# STM32U5Gx register map
File version: 1.0
CPU: CM33 r0p1, little endian, MPU, FPU, 4 interrupt priority bits
Registers are 32-bit, read-write, reset 0x0 unless marked. A register's access mark holds for its fields unless they carry their own. Offsets are from the block's base; [hi:lo] are bit positions.

## ADC12_Common — Analog-to-Digital Converter
Base 0x42028300
Same registers: SEC_ADC12_Common 0x52028300
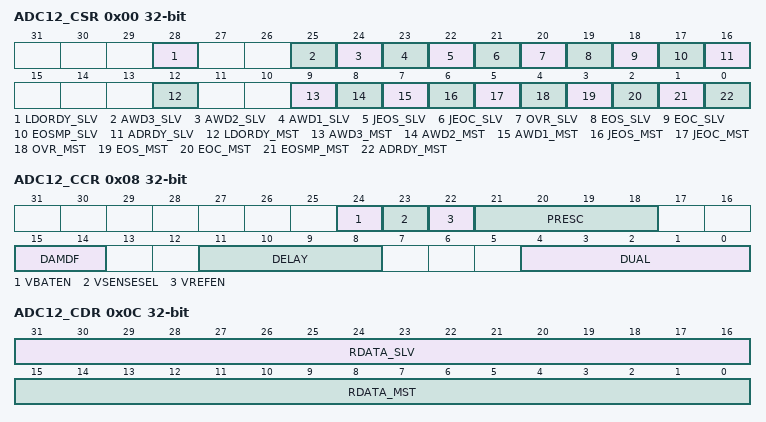
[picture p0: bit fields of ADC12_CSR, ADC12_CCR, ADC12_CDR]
0x00 ADC12_CSR ro — ADC common status register
  [28] LDORDY_SLV — ADC voltage regulator ready flag of the slave ADC This bit is a copy of the LDORDY bit of the corresponding ADCx+1_ISR register.
  [25] AWD3_SLV — Analog watchdog 3 flag of the slave ADC This bit is a copy of the AWD3 bit in the corresponding ADCx+1_ISR register.
  [24] AWD2_SLV — Analog watchdog 2 flag of the slave ADC This bit is a copy of the AWD2 bit in the corresponding ADCx+1_ISR register.
  [23] AWD1_SLV — Analog watchdog 1 flag of the slave ADC This bit is a copy of the AWD1 bit in the corresponding ADCx+1_ISR register.
  [22] JEOS_SLV — End of injected sequence flag of the slave ADC This bit is a copy of the JEOS bit in the corresponding ADCx+1_ISR register.
  [21] JEOC_SLV — End of injected conversion flag of the slave ADC This bit is a copy of the JEOC bit in the corresponding ADCx+1_ISR register.
  [20] OVR_SLV — Overrun flag of the slave ADC This bit is a copy of the OVR bit in the corresponding ADCx+1_ISR register.
  [19] EOS_SLV — End of regular sequence flag of the slave ADC This bit is a copy of the EOS bit in the corresponding ADCx+1_ISR register.
  [18] EOC_SLV — End of regular conversion of the slave ADC This bit is a copy of the EOC bit in the corresponding ADCx+1_ISR register.
  [17] EOSMP_SLV — End of Sampling phase flag of the slave ADC This bit is a copy of the EOSMP2 bit in the corresponding ADCx+1_ISR register.
  [16] ADRDY_SLV — Slave ADC ready This bit is a copy of the ADRDY bit in the corresponding ADCx+1_ISR register.
  [12] LDORDY_MST — ADC voltage regulator ready flag of the master ADC This bit is a copy of the LDORDY bit of the corresponding ADC_ISR register.
  [9] AWD3_MST — Analog watchdog 3 flag of the master ADC This bit is a copy of the AWD3 bit in the corresponding ADC_ISR register.
  [8] AWD2_MST — Analog watchdog 2 flag of the master ADC This bit is a copy of the AWD2 bit in the corresponding ADC_ISR register.
  [7] AWD1_MST — Analog watchdog 1 flag of the master ADC This bit is a copy of the AWD1 bit in the corresponding ADC_ISR register.
  [6] JEOS_MST — End of injected sequence flag of the master ADC This bit is a copy of the JEOS bit in the corresponding ADC_ISR register.
  [5] JEOC_MST — End of injected conversion flag of the master ADC This bit is a copy of the JEOC bit in the corresponding ADC_ISR register.
  [4] OVR_MST — Overrun flag of the master ADC This bit is a copy of the OVR bit in the corresponding ADC_ISR register.
  [3] EOS_MST — End of regular sequence flag of the master ADC This bit is a copy of the EOS bit in the corresponding ADC_ISR register.
  [2] EOC_MST — End of regular conversion of the master ADC This bit is a copy of the EOC bit in the corresponding ADC_ISR register.
  [1] EOSMP_MST — End of Sampling phase flag of the master ADC This bit is a copy of the EOSMP bit in the corresponding ADC_ISR register.
  [0] ADRDY_MST — Master ADC ready This bit is a copy of the ADRDY bit in the corresponding ADC_ISR register.
0x08 ADC12_CCR — ADC_CCR system control register
  [24] VBATEN — VBAT enable This bit is set and cleared by software to control the VBAT channel. Note: The software is allowed to write this bit only when the ADCs are disabled (ADCAL = 0, JADSTART = 0, ADSTART = 0, ADSTP = 0, ADDIS = 0 and ADEN = 0).
    0=VBAT channel disabled; 1=VBAT channel enabled
  [23] VSENSESEL — Temperature sensor voltage selection This bit is set and cleared by software to control the temperature sensor channel. Note: The software is allowed to write this bit only when the ADCs are disabled (ADCAL = 0, JADSTART = 0, ADSTART = 0, ADSTP = 0, ADDIS = 0 and ADEN = 0).
    0=Temperature sensor channel disabled; 1=Temperature sensor channel enabled
  [22] VREFEN — VREFINT enable This bit is set and cleared by software to enable/disable the VREFINT buffer. Note: The software is allowed to write this bit only when the ADCs are disabled (ADCAL = 0, JADSTART = 0, ADSTART = 0, ADSTP = 0, ADDIS = 0 and ADEN = 0).
    0=VREFINT channel disabled; 1=VREFINT channel enabled
  [21:18] PRESC — ADC prescaler These bits are set and cleared by software to select the frequency of the ADC clock. The clock is common to all ADCs. Others: Reserved, must not be used Note: The software is allowed to write this bit only when the ADCs are disabled (ADCAL = 0, JADSTART = 0, ADSTART = 0, ADSTP = 0, ADDIS = 0 and ADEN = 0).
    0=input ADC clock not divided; 1=input ADC clock divided by 2; 2=input ADC clock divided by 4; 3=input ADC clock divided by 6; 4=input ADC clock divided by 8; 5=input ADC clock divided by 10; 6=input ADC clock divided by 12; 7=input ADC clock divided by 16; 8=input ADC clock divided by 32; 9=input ADC clock divided by 64; 10=input ADC clock divided by 128; 11=input ADC clock divided by 256
  [15:14] DAMDF — Dual ADC Mode Data Format This bit-field is set and cleared by software. It specifies the data format in the common data register ADC12_CDR. Note: The software is allowed to write these bits only when ADSTART = 0 (which ensures that no regular conversion is ongoing).
    0=Dual ADC mode without data packing (ADC12_CDR and ADC12_CDR2 registers not used); 2=Data formatting mode for 32 down to 10-bit resolution; 3=Data formatting mode for 8-bit resolution
  [11:8] DELAY — Delay between the end of the master ADC sampling phase and the beginning of the slave ADC sampling phase. These bits are set and cleared by software. These bits are used in dual interleaved modes. Refer to for the value of ADC resolution versus DELAY bits values. Note: The software is allowed to write these bits only when the ADCs are disabled (ADCAL = 0, JADSTART = 0, ADSTART = 0, ADSTP = 0, ADDIS = 0 and ADEN = 0).
  [4:0] DUAL — Dual ADC mode selection These bits are written by software to select the operating mode. All the ADCs are independent: The configurations 00001 to 01001 correspond to the following operating modes: Dual mode, master and slave ADCs working together: All other combinations are reserved and must not be programmed Note: The software is allowed to write these bits only when the ADCs are disabled (ADCAL = 0, JADSTART = 0, ADSTART = 0, ADSTP = 0, ADDIS = 0 and ADEN = 0).
    0=Independent mode; 1=Combined regular simultaneous + injected simultaneous mode; 2=Combined regular simultaneous + alternate trigger mode; 3=Combined Interleaved mode + injected simultaneous mode; 5=Injected simultaneous mode only; 6=Regular simultaneous mode only; 7=Interleaved mode only; 9=Alternate trigger mode only
0x0C ADC12_CDR ro — ADC common regular data register for dual mode
  [31:16] RDATA_SLV — Regular data of the slave ADC In dual mode, these bits contain the regular data of the slave ADC. Refer to Dual ADC modes. The data alignment is applied as described in offset (ADC_DR, ADC_JDRy, OFFSETy, OFFSETy_CH, OVSS, LSHIFT, USAT, SSAT))
  [15:0] RDATA_MST — Regular data of the master ADC. In dual mode, these bits contain the regular data of the master ADC. Refer to . The data alignment is applied as described in offset (ADC_DR, ADC_JDRy, OFFSETy, OFFSETy_CH, OVSS, LSHIFT, USAT, SSAT)) In DAMDF[1:0] = 11 mode, bits 15:8 contains SLV_ADC_DR[7:0], bits 7:0 contains MST_ADC_DR[7:0].
0x10 ADC12_CDR2 ro — ADC common regular data register for 32-bit dual mode
  [31:0] RDATA_ALT — Regular data of the master/slave alternated ADCs In dual mode, these bits alternatively contains the regular 32-bit data of the master and the slave ADC. Refer to . The data alignment is applied as described in (ADC_DR, ADC_JDRy, OFFSETy, OFFSETy_CH, OVSS, LSHIFT, USAT, SSAT).

## Notices in the file
Copyright (c) 2023 STMicroelectronics.
SPDX-License-Identifier: Apache-2.0
Licensed under the Apache License, Version 2.0 (the "License");
you may not use this file except in compliance with the License.
You may obtain a copy of the License at
http://www.apache.org/licenses/LICENSE-2.0
Unless required by applicable law or agreed to in writing, software
distributed under the License is distributed on an "AS IS" BASIS,
WITHOUT WARRANTIES OR CONDITIONS OF ANY KIND, either express or implied.
See the License for the specific language governing permissions and
limitations under the License.
